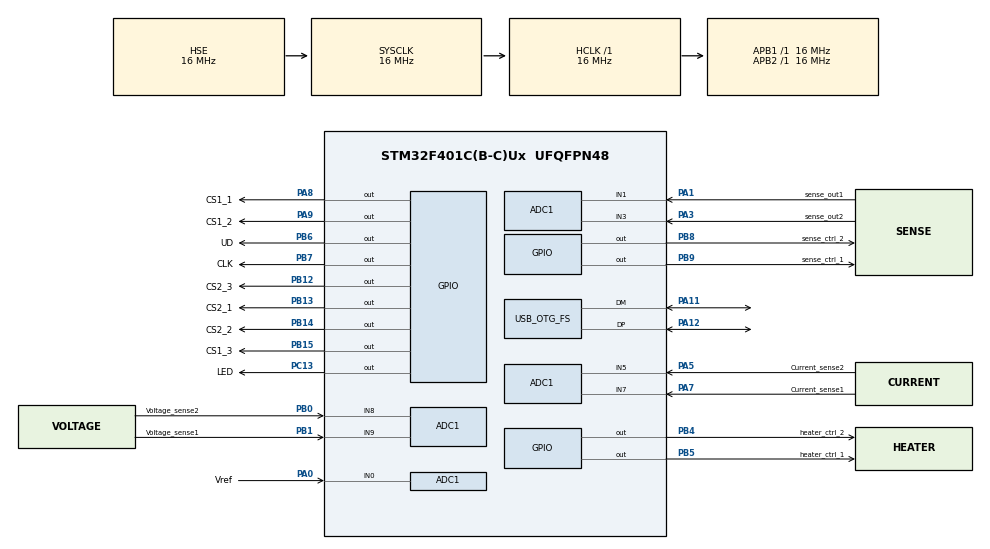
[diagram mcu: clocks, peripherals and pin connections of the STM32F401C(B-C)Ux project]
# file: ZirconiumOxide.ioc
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ADC1.Channel-0\#ChannelRegularConversion=ADC_CHANNEL_1
ADC1.Channel-1\#ChannelRegularConversion=ADC_CHANNEL_3
ADC1.Channel-2\#ChannelRegularConversion=ADC_CHANNEL_7
ADC1.Channel-3\#ChannelRegularConversion=ADC_CHANNEL_5
ADC1.Channel-4\#ChannelRegularConversion=ADC_CHANNEL_9
ADC1.Channel-5\#ChannelRegularConversion=ADC_CHANNEL_8
ADC1.Channel-6\#ChannelRegularConversion=ADC_CHANNEL_0
ADC1.DMAContinuousRequests=ENABLE
ADC1.EOCSelection=ADC_EOC_SEQ_CONV
ADC1.ExternalTrigConv=ADC_EXTERNALTRIGCONV_T2_TRGO
ADC1.NbrOfConversion=7
ADC1.NbrOfConversionFlag=1
ADC1.Rank-0\#ChannelRegularConversion=1
ADC1.Rank-1\#ChannelRegularConversion=2
ADC1.Rank-2\#ChannelRegularConversion=3
ADC1.Rank-3\#ChannelRegularConversion=4
ADC1.Rank-4\#ChannelRegularConversion=5
ADC1.Rank-5\#ChannelRegularConversion=6
ADC1.Rank-6\#ChannelRegularConversion=7
ADC1.SamplingTime-0\#ChannelRegularConversion=ADC_SAMPLETIME_144CYCLES
ADC1.SamplingTime-1\#ChannelRegularConversion=ADC_SAMPLETIME_144CYCLES
ADC1.SamplingTime-2\#ChannelRegularConversion=ADC_SAMPLETIME_144CYCLES
ADC1.SamplingTime-3\#ChannelRegularConversion=ADC_SAMPLETIME_144CYCLES
ADC1.SamplingTime-4\#ChannelRegularConversion=ADC_SAMPLETIME_144CYCLES
ADC1.SamplingTime-5\#ChannelRegularConversion=ADC_SAMPLETIME_144CYCLES
ADC1.SamplingTime-6\#ChannelRegularConversion=ADC_SAMPLETIME_144CYCLES
ADC1.ScanConvMode=ENABLE
ADC1.master=1
Dma.ADC1.0.Direction=DMA_PERIPH_TO_MEMORY
Dma.ADC1.0.FIFOMode=DMA_FIFOMODE_DISABLE
Dma.ADC1.0.Instance=DMA2_Stream0
Dma.ADC1.0.MemDataAlignment=DMA_MDATAALIGN_HALFWORD
Dma.ADC1.0.MemInc=DMA_MINC_ENABLE
Dma.ADC1.0.Mode=DMA_CIRCULAR
Dma.ADC1.0.PeriphDataAlignment=DMA_PDATAALIGN_HALFWORD
Dma.ADC1.0.PeriphInc=DMA_PINC_DISABLE
Dma.ADC1.0.Priority=DMA_PRIORITY_LOW
Dma.Request0=ADC1
Mcu.Family=STM32F4
Mcu.Name=STM32F401C(B-C)Ux
Mcu.Package=UFQFPN48
NVIC.DMA2_Stream0_IRQn=true\:1\:0\:true\:false\:true\:false\:true\:true
NVIC.OTG_FS_IRQn=true\:1\:0\:true\:false\:true\:true\:true\:true
NVIC.PriorityGroup=NVIC_PRIORITYGROUP_4
NVIC.TIM2_IRQn=true\:1\:0\:true\:false\:true\:true\:true\:true
NVIC.TIM5_IRQn=true\:1\:0\:true\:false\:true\:true\:true\:true
PA0-WKUP.GPIO_Label=Vref
PA0-WKUP.Signal=ADCx_IN0
PA1.GPIO_Label=sense_out1
PA1.Signal=ADCx_IN1
PA11.Mode=Device_Only
PA11.Signal=USB_OTG_FS_DM
PA12.Mode=Device_Only
PA12.Signal=USB_OTG_FS_DP
PA13.Mode=Trace_Asynchronous_SW
PA13.Signal=SYS_JTMS-SWDIO
PA14.Mode=Trace_Asynchronous_SW
PA14.Signal=SYS_JTCK-SWCLK
PA3.GPIO_Label=sense_out2
PA3.Signal=ADCx_IN3
PA5.GPIO_Label=Current_sense2
PA5.Signal=ADCx_IN5
PA7.GPIO_Label=Current_sense1
PA7.Signal=ADCx_IN7
PA8.GPIO_Label=CS1_1
PA8.Signal=GPIO_Output
PA9.GPIO_Label=CS1_2
PA9.Signal=GPIO_Output
PB0.GPIO_Label=Voltage_sense2
PB0.Signal=ADCx_IN8
PB1.GPIO_Label=Voltage_sense1
PB1.Signal=ADCx_IN9
PB12.GPIO_Label=CS2_3
PB12.Signal=GPIO_Output
PB13.GPIO_Label=CS2_1
PB13.Signal=GPIO_Output
PB14.GPIO_Label=CS2_2
PB14.Signal=GPIO_Output
PB15.GPIO_Label=CS1_3
PB15.Signal=GPIO_Output
PB3.Mode=Trace_Asynchronous_SW
PB3.Signal=SYS_JTDO-SWO
PB4.GPIO_Label=heater_ctrl_2
PB4.Signal=GPIO_Output
PB5.GPIO_Label=heater_ctrl_1
PB5.Signal=GPIO_Output
PB6.GPIO_Label=UD
PB6.Signal=GPIO_Output
PB7.GPIO_Label=CLK
PB7.Signal=GPIO_Output
PB8.GPIO_Label=sense_ctrl_2
PB8.Signal=GPIO_Output
PB9.GPIO_Label=sense_ctrl_1
PB9.Signal=GPIO_Output
PC13-ANTI_TAMP.GPIO_Label=LED
PC13-ANTI_TAMP.Signal=GPIO_Output
PH0\ -\ OSC_IN.Mode=HSE-External-Oscillator
PH0\ -\ OSC_IN.Signal=RCC_OSC_IN
PH1\ -\ OSC_OUT.Mode=HSE-External-Oscillator
PH1\ -\ OSC_OUT.Signal=RCC_OSC_OUT
ProjectManager.HeapSize=0x200
ProjectManager.StackSize=0x400
ProjectManager.TargetToolchain=Makefile
RCC.48MHZClocksFreq_Value=48000000
RCC.AHBFreq_Value=16000000
RCC.APB1Freq_Value=16000000
RCC.APB2Freq_Value=16000000
RCC.CortexFreq_Value=16000000
RCC.HSE_VALUE=16000000
RCC.HSI_VALUE=16000000
RCC.LSE_VALUE=32768
RCC.PLLM=8
RCC.PLLN=72
RCC.PLLQ=3
RCC.SYSCLKFreq_VALUE=16000000
RCC.SYSCLKSource=RCC_SYSCLKSOURCE_HSE
RCC.VCOOutputFreq_Value=144000000
SH.ADCx_IN0.0=ADC1_IN0,IN0
SH.ADCx_IN1.0=ADC1_IN1,IN1
SH.ADCx_IN3.0=ADC1_IN3,IN3
SH.ADCx_IN5.0=ADC1_IN5,IN5
SH.ADCx_IN7.0=ADC1_IN7,IN7
SH.ADCx_IN8.0=ADC1_IN8,IN8
SH.ADCx_IN9.0=ADC1_IN9,IN9
TIM2.AutoReloadPreload=TIM_AUTORELOAD_PRELOAD_ENABLE
TIM2.Period=9
TIM2.Prescaler=399
TIM2.TIM_MasterOutputTrigger=TIM_TRGO_UPDATE
TIM2.TIM_MasterSlaveMode=TIM_MASTERSLAVEMODE_ENABLE
TIM5.AutoReloadPreload=TIM_AUTORELOAD_PRELOAD_ENABLE
TIM5.Period=15999
TIM5.Prescaler=99
TIM5.TIM_MasterOutputTrigger=TIM_TRGO_UPDATE
TIM5.TIM_MasterSlaveMode=TIM_MASTERSLAVEMODE_ENABLE
USB_DEVICE.CLASS_NAME_FS=CDC
USB_DEVICE.VirtualMode=Cdc
USB_DEVICE.VirtualModeFS=Cdc_FS
USB_OTG_FS.VirtualMode=Device_Only
VP_CRC_VS_CRC.Mode=CRC_Activate
VP_TIM2_VS_ClockSourceINT.Mode=Internal
VP_TIM5_VS_ClockSourceINT.Mode=Internal
VP_USB_DEVICE_VS_USB_DEVICE_CDC_FS.Mode=CDC_FS
VP_WWDG_VS_WWDG.Mode=WWDG_Activate
WWDG.Counter=127
WWDG.Prescaler=WWDG_PRESCALER_8
WWDG.Window=127
board=custom

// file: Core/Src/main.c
/* USER CODE BEGIN Header */
/**
  ******************************************************************************
  * @file           : main.c
  * @brief          : Main program body
  ******************************************************************************
  * @attention
  *
  * Copyright (c) 2022 STMicroelectronics.
  * All rights reserved.
  *
  * This software is licensed under terms that can be found in the LICENSE file
  * in the root directory of this software component.
  * If no LICENSE file comes with this software, it is provided AS-IS.
  *
  ******************************************************************************
  */
/* USER CODE END Header */
#include "main.h"
#include "usb_device.h"

/* USER CODE BEGIN Includes */
#include "oxygen.h"
#include "CAProtocolStm.h"
#include "usb_cdc_fops.h"
/* USER CODE END Includes */

ADC_HandleTypeDef hadc1;
DMA_HandleTypeDef hdma_adc1;

CRC_HandleTypeDef hcrc;

TIM_HandleTypeDef htim2;
TIM_HandleTypeDef htim5;

WWDG_HandleTypeDef hwwdg;

void SystemClock_Config(void);
static void MX_GPIO_Init(void);
static void MX_DMA_Init(void);
static void MX_ADC1_Init(void);
static void MX_WWDG_Init(void);
static void MX_TIM2_Init(void);
static void MX_TIM5_Init(void);
static void MX_CRC_Init(void);

int main(void)
{

  /* MCU Configuration--------------------------------------------------------*/

  /* Reset of all peripherals, Initializes the Flash interface and the Systick. */
  HAL_Init();

  /* Configure the system clock */
  SystemClock_Config();

  /* USER CODE BEGIN SysInit */
  const char* bootMsg = CAonBoot();
  /* USER CODE END SysInit */

  /* Initialize all configured peripherals */
  MX_GPIO_Init();
  MX_DMA_Init();
  MX_ADC1_Init();
  MX_WWDG_Init();
  MX_TIM2_Init();
  MX_USB_DEVICE_Init();
  MX_TIM5_Init();
  MX_CRC_Init();
  /* USER CODE BEGIN 2 */
  oxygenInit(&hadc1, &htim2, &htim5, &hcrc);
  /* USER CODE END 2 */

  /* Infinite loop */
  /* USER CODE BEGIN WHILE */
  while (1)
  {
      HAL_WWDG_Refresh(&hwwdg);
      oxygenLoop(bootMsg);
    /* USER CODE END WHILE */

  }
}

void SystemClock_Config(void)
{
  RCC_OscInitTypeDef RCC_OscInitStruct = {0};
  RCC_ClkInitTypeDef RCC_ClkInitStruct = {0};

  /** Configure the main internal regulator output voltage
  */
  __HAL_RCC_PWR_CLK_ENABLE();
  __HAL_PWR_VOLTAGESCALING_CONFIG(PWR_REGULATOR_VOLTAGE_SCALE2);

  /** Initializes the RCC Oscillators according to the specified parameters
  * in the RCC_OscInitTypeDef structure.
  */
  RCC_OscInitStruct.OscillatorType = RCC_OSCILLATORTYPE_HSE;
  RCC_OscInitStruct.HSEState = RCC_HSE_ON;
  RCC_OscInitStruct.PLL.PLLState = RCC_PLL_ON;
  RCC_OscInitStruct.PLL.PLLSource = RCC_PLLSOURCE_HSE;
  RCC_OscInitStruct.PLL.PLLM = 8;
  RCC_OscInitStruct.PLL.PLLN = 72;
  RCC_OscInitStruct.PLL.PLLP = RCC_PLLP_DIV2;
  RCC_OscInitStruct.PLL.PLLQ = 3;
  if (HAL_RCC_OscConfig(&RCC_OscInitStruct) != HAL_OK)
  {
    Error_Handler();
  }

  /** Initializes the CPU, AHB and APB buses clocks
  */
  RCC_ClkInitStruct.ClockType = RCC_CLOCKTYPE_HCLK|RCC_CLOCKTYPE_SYSCLK
                              |RCC_CLOCKTYPE_PCLK1|RCC_CLOCKTYPE_PCLK2;
  RCC_ClkInitStruct.SYSCLKSource = RCC_SYSCLKSOURCE_HSE;
  RCC_ClkInitStruct.AHBCLKDivider = RCC_SYSCLK_DIV1;
  RCC_ClkInitStruct.APB1CLKDivider = RCC_HCLK_DIV1;
  RCC_ClkInitStruct.APB2CLKDivider = RCC_HCLK_DIV1;

  if (HAL_RCC_ClockConfig(&RCC_ClkInitStruct, FLASH_LATENCY_0) != HAL_OK)
  {
    Error_Handler();
  }
}

static void MX_ADC1_Init(void)
{

  ADC_ChannelConfTypeDef sConfig = {0};

  /** Configure the global features of the ADC (Clock, Resolution, Data Alignment and number of conversion)
  */
  hadc1.Instance = ADC1;
  hadc1.Init.ClockPrescaler = ADC_CLOCK_SYNC_PCLK_DIV2;
  hadc1.Init.Resolution = ADC_RESOLUTION_12B;
  hadc1.Init.ScanConvMode = ENABLE;
  hadc1.Init.ContinuousConvMode = DISABLE;
  hadc1.Init.DiscontinuousConvMode = DISABLE;
  hadc1.Init.ExternalTrigConvEdge = ADC_EXTERNALTRIGCONVEDGE_RISING;
  hadc1.Init.ExternalTrigConv = ADC_EXTERNALTRIGCONV_T2_TRGO;
  hadc1.Init.DataAlign = ADC_DATAALIGN_RIGHT;
  hadc1.Init.NbrOfConversion = 7;
  hadc1.Init.DMAContinuousRequests = ENABLE;
  hadc1.Init.EOCSelection = ADC_EOC_SEQ_CONV;
  if (HAL_ADC_Init(&hadc1) != HAL_OK)
  {
    Error_Handler();
  }

  /** Configure for the selected ADC regular channel its corresponding rank in the sequencer and its sample time.
  */
  sConfig.Channel = ADC_CHANNEL_1;
  sConfig.Rank = 1;
  sConfig.SamplingTime = ADC_SAMPLETIME_144CYCLES;
  if (HAL_ADC_ConfigChannel(&hadc1, &sConfig) != HAL_OK)
  {
    Error_Handler();
  }

  /** Configure for the selected ADC regular channel its corresponding rank in the sequencer and its sample time.
  */
  sConfig.Channel = ADC_CHANNEL_3;
  sConfig.Rank = 2;
  if (HAL_ADC_ConfigChannel(&hadc1, &sConfig) != HAL_OK)
  {
    Error_Handler();
  }

  /** Configure for the selected ADC regular channel its corresponding rank in the sequencer and its sample time.
  */
  sConfig.Channel = ADC_CHANNEL_7;
  sConfig.Rank = 3;
  if (HAL_ADC_ConfigChannel(&hadc1, &sConfig) != HAL_OK)
  {
    Error_Handler();
  }

  /** Configure for the selected ADC regular channel its corresponding rank in the sequencer and its sample time.
  */
  sConfig.Channel = ADC_CHANNEL_5;
  sConfig.Rank = 4;
  if (HAL_ADC_ConfigChannel(&hadc1, &sConfig) != HAL_OK)
  {
    Error_Handler();
  }

  /** Configure for the selected ADC regular channel its corresponding rank in the sequencer and its sample time.
  */
  sConfig.Channel = ADC_CHANNEL_9;
  sConfig.Rank = 5;
  if (HAL_ADC_ConfigChannel(&hadc1, &sConfig) != HAL_OK)
  {
    Error_Handler();
  }

  /** Configure for the selected ADC regular channel its corresponding rank in the sequencer and its sample time.
  */
  sConfig.Channel = ADC_CHANNEL_8;
  sConfig.Rank = 6;
  if (HAL_ADC_ConfigChannel(&hadc1, &sConfig) != HAL_OK)
  {
    Error_Handler();
  }

  /** Configure for the selected ADC regular channel its corresponding rank in the sequencer and its sample time.
  */
  sConfig.Channel = ADC_CHANNEL_0;
  sConfig.Rank = 7;
  if (HAL_ADC_ConfigChannel(&hadc1, &sConfig) != HAL_OK)
  {
    Error_Handler();
  }

}

static void MX_CRC_Init(void)
{

  hcrc.Instance = CRC;
  if (HAL_CRC_Init(&hcrc) != HAL_OK)
  {
    Error_Handler();
  }

}

static void MX_TIM2_Init(void)
{

  TIM_ClockConfigTypeDef sClockSourceConfig = {0};
  TIM_MasterConfigTypeDef sMasterConfig = {0};

  htim2.Instance = TIM2;
  htim2.Init.Prescaler = 399;
  htim2.Init.CounterMode = TIM_COUNTERMODE_UP;
  htim2.Init.Period = 9;
  htim2.Init.ClockDivision = TIM_CLOCKDIVISION_DIV1;
  htim2.Init.AutoReloadPreload = TIM_AUTORELOAD_PRELOAD_ENABLE;
  if (HAL_TIM_Base_Init(&htim2) != HAL_OK)
  {
    Error_Handler();
  }
  sClockSourceConfig.ClockSource = TIM_CLOCKSOURCE_INTERNAL;
  if (HAL_TIM_ConfigClockSource(&htim2, &sClockSourceConfig) != HAL_OK)
  {
    Error_Handler();
  }
  sMasterConfig.MasterOutputTrigger = TIM_TRGO_UPDATE;
  sMasterConfig.MasterSlaveMode = TIM_MASTERSLAVEMODE_ENABLE;
  if (HAL_TIMEx_MasterConfigSynchronization(&htim2, &sMasterConfig) != HAL_OK)
  {
    Error_Handler();
  }

}

static void MX_TIM5_Init(void)
{

  TIM_ClockConfigTypeDef sClockSourceConfig = {0};
  TIM_MasterConfigTypeDef sMasterConfig = {0};

  htim5.Instance = TIM5;
  htim5.Init.Prescaler = 99;
  htim5.Init.CounterMode = TIM_COUNTERMODE_UP;
  htim5.Init.Period = 15999;
  htim5.Init.ClockDivision = TIM_CLOCKDIVISION_DIV1;
  htim5.Init.AutoReloadPreload = TIM_AUTORELOAD_PRELOAD_ENABLE;
  if (HAL_TIM_Base_Init(&htim5) != HAL_OK)
  {
    Error_Handler();
  }
  sClockSourceConfig.ClockSource = TIM_CLOCKSOURCE_INTERNAL;
  if (HAL_TIM_ConfigClockSource(&htim5, &sClockSourceConfig) != HAL_OK)
  {
    Error_Handler();
  }
  sMasterConfig.MasterOutputTrigger = TIM_TRGO_UPDATE;
  sMasterConfig.MasterSlaveMode = TIM_MASTERSLAVEMODE_ENABLE;
  if (HAL_TIMEx_MasterConfigSynchronization(&htim5, &sMasterConfig) != HAL_OK)
  {
    Error_Handler();
  }

}

static void MX_WWDG_Init(void)
{

  hwwdg.Instance = WWDG;
  hwwdg.Init.Prescaler = WWDG_PRESCALER_8;
  hwwdg.Init.Window = 127;
  hwwdg.Init.Counter = 127;
  hwwdg.Init.EWIMode = WWDG_EWI_DISABLE;
  if (HAL_WWDG_Init(&hwwdg) != HAL_OK)
  {
    Error_Handler();
  }

}

static void MX_DMA_Init(void)
{

  /* DMA controller clock enable */
  __HAL_RCC_DMA2_CLK_ENABLE();

  /* DMA interrupt init */
  /* DMA2_Stream0_IRQn interrupt configuration */
  HAL_NVIC_SetPriority(DMA2_Stream0_IRQn, 1, 0);
  HAL_NVIC_EnableIRQ(DMA2_Stream0_IRQn);

}

static void MX_GPIO_Init(void)
{
  GPIO_InitTypeDef GPIO_InitStruct = {0};

  /* GPIO Ports Clock Enable */
  __HAL_RCC_GPIOC_CLK_ENABLE();
  __HAL_RCC_GPIOH_CLK_ENABLE();
  __HAL_RCC_GPIOA_CLK_ENABLE();
  __HAL_RCC_GPIOB_CLK_ENABLE();

  /*Configure GPIO pin Output Level */
  HAL_GPIO_WritePin(LED_GPIO_Port, LED_Pin, GPIO_PIN_RESET);

  /*Configure GPIO pin Output Level */
  HAL_GPIO_WritePin(GPIOB, CS2_3_Pin|CS2_1_Pin|CS2_2_Pin|CS1_3_Pin
                          |heater_ctrl_2_Pin|heater_ctrl_1_Pin|UD_Pin|CLK_Pin
                          |sense_ctrl_2_Pin|sense_ctrl_1_Pin, GPIO_PIN_RESET);

  /*Configure GPIO pin Output Level */
  HAL_GPIO_WritePin(GPIOA, CS1_1_Pin|CS1_2_Pin, GPIO_PIN_RESET);

  /*Configure GPIO pin : LED_Pin */
  GPIO_InitStruct.Pin = LED_Pin;
  GPIO_InitStruct.Mode = GPIO_MODE_OUTPUT_PP;
  GPIO_InitStruct.Pull = GPIO_NOPULL;
  GPIO_InitStruct.Speed = GPIO_SPEED_FREQ_LOW;
  HAL_GPIO_Init(LED_GPIO_Port, &GPIO_InitStruct);

  /*Configure GPIO pins : CS2_3_Pin CS2_1_Pin CS2_2_Pin CS1_3_Pin
                           heater_ctrl_2_Pin heater_ctrl_1_Pin UD_Pin CLK_Pin
                           sense_ctrl_2_Pin sense_ctrl_1_Pin */
  GPIO_InitStruct.Pin = CS2_3_Pin|CS2_1_Pin|CS2_2_Pin|CS1_3_Pin
                          |heater_ctrl_2_Pin|heater_ctrl_1_Pin|UD_Pin|CLK_Pin
                          |sense_ctrl_2_Pin|sense_ctrl_1_Pin;
  GPIO_InitStruct.Mode = GPIO_MODE_OUTPUT_PP;
  GPIO_InitStruct.Pull = GPIO_NOPULL;
  GPIO_InitStruct.Speed = GPIO_SPEED_FREQ_LOW;
  HAL_GPIO_Init(GPIOB, &GPIO_InitStruct);

  /*Configure GPIO pins : CS1_1_Pin CS1_2_Pin */
  GPIO_InitStruct.Pin = CS1_1_Pin|CS1_2_Pin;
  GPIO_InitStruct.Mode = GPIO_MODE_OUTPUT_PP;
  GPIO_InitStruct.Pull = GPIO_NOPULL;
  GPIO_InitStruct.Speed = GPIO_SPEED_FREQ_LOW;
  HAL_GPIO_Init(GPIOA, &GPIO_InitStruct);

}

void Error_Handler(void)
{
  __disable_irq();
  while (1)
  {
  }
}
